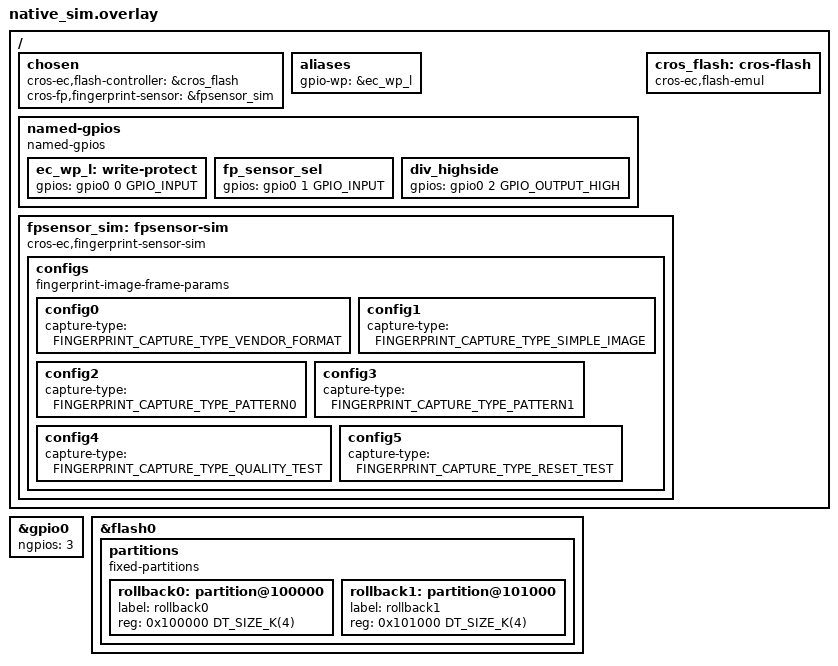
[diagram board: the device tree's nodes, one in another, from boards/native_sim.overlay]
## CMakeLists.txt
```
# Copyright 2024 The ChromiumOS Authors
# Use of this source code is governed by a BSD-style license that can be
# found in the LICENSE file.

cmake_minimum_required(VERSION 3.13.1)
find_package(Zephyr REQUIRED HINTS "${ZEPHYR_BASE}")
project(fpsensor_task_test)

target_sources(app PRIVATE src/mock_fingerprint_algorithm.c)
target_sources_ifdef(CONFIG_LINK_TEST_SUITE_FINGERPRINT_CAPTURE app PRIVATE
	src/fpsensor_capture.cc)
target_sources_ifdef(CONFIG_LINK_TEST_SUITE_FINGERPRINT_ENROLL app PRIVATE
	src/fpsensor_enroll.cc)
target_sources_ifdef(CONFIG_LINK_TEST_SUITE_FINGERPRINT_FINGER_PRESENCE app PRIVATE
	src/fpsensor_finger_presence.cc)
target_sources_ifdef(CONFIG_LINK_TEST_SUITE_FINGERPRINT_INIT app PRIVATE
	src/fpsensor_init.cc)
target_sources_ifdef(CONFIG_LINK_TEST_SUITE_FINGERPRINT_MATCH app PRIVATE
	src/fpsensor_match.cc)
target_sources_ifdef(CONFIG_LINK_TEST_SUITE_FINGERPRINT_SHIM app PRIVATE
	src/fpsensor_shim.cc)
target_sources_ifdef(CONFIG_LINK_TEST_SUITE_FINGERPRINT_TEMPLATE app PRIVATE
	src/fpsensor_template.cc)
target_sources_ifdef(CONFIG_LINK_TEST_SUITE_FINGERPRINT_UTILS app PRIVATE
	src/fpsensor_utils.cc)
target_sources_ifdef(CONFIG_LINK_TEST_SUITE_FINGERPRINT_DEBUG app PRIVATE
	src/fpsensor_debug.cc)
target_sources_ifdef(CONFIG_LINK_TEST_SUITE_FINGERPRINT_COMMANDS app PRIVATE
	src/fpsensor_commands.cc
	src/fpsensor_vendor_command.cc
	src/fpsensor_sdcp_command.cc)
target_sources_ifdef(CONFIG_LINK_TEST_SUITE_FINGERPRINT_FRAME_SIZE app PRIVATE
	src/fpsensor_frame_size.cc)
```

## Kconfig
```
# Copyright 2024 The ChromiumOS Authors
# Use of this source code is governed by a BSD-style license that can be
# found in the LICENSE file.

config LINK_TEST_SUITE_FINGERPRINT_CAPTURE
	bool "Link fingerprint capture tests"
	help
	  Link and execute fingerprint subsystem tests that focus
	  on finger capture.

config LINK_TEST_SUITE_FINGERPRINT_ENROLL
	bool "Link fingerprint enroll tests"
	help
	  Link and execute fingerprint subsystem tests that focus
	  on template enrollment.

config LINK_TEST_SUITE_FINGERPRINT_FINGER_PRESENCE
	bool "Link fingerprint finger presence tests"
	help
	  Link and execute fingerprint subsystem tests that focus
	  on finger presence.

config LINK_TEST_SUITE_FINGERPRINT_INIT
	bool "Link fingerprint init tests"
	help
	  Link and execute fingerprint subsystem tests that focus
	  on initializing TPM seed and context.

config LINK_TEST_SUITE_FINGERPRINT_MATCH
	bool "Link fingerprint match tests"
	help
	  Link and execute fingerprint subsystem tests that focus
	  on finger matching.

config LINK_TEST_SUITE_FINGERPRINT_SHIM
	bool "Link fingerprint shim tests"
	help
	  Link and execute fingerprint subsystem tests that focus
	  on fpsensor shim.

config LINK_TEST_SUITE_FINGERPRINT_TEMPLATE
	bool "Link fingerprint template tests"
	help
	  Link and execute fingerprint subsystem tests that focus
	  on finger templates.

config LINK_TEST_SUITE_FINGERPRINT_UTILS
	bool "Link fingerprint utils tests"
	help
	  Link and execute fingerprint subsystem tests that focus
	  on finger utils.

config LINK_TEST_SUITE_FINGERPRINT_DEBUG
	bool "Link fingerprint debug tests"
	help
	  Link and execute fingerprint subsystem tests that focus
	  on finger debug.

config LINK_TEST_SUITE_FINGERPRINT_COMMANDS
	bool "Link fingerprint commands tests"
	help
	  Link and execute fingerprint subsystem tests that focus
	  on fingerprint host and console commands.

config LINK_TEST_SUITE_FINGERPRINT_FRAME_SIZE
	bool "Link fingerprint frame size tests"
	help
	  Link and execute fingerprint subsystem tests that focus
	  on finger frame size.

config LINK_TEST_SUITE_FINGERPRINT_BTN_IGN
	bool "Link fingerprint btn ign tests"
	help
	  Link and execute fingerprint subsystem tests that focus
	  on btn ign.

source "Kconfig.zephyr"
```

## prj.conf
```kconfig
# Copyright 2024 The ChromiumOS Authors
# Use of this source code is governed by a BSD-style license that can be
# found in the LICENSE file.

CONFIG_TEST=y
CONFIG_ZTEST=y
CONFIG_EMUL=y
CONFIG_FLASH=y
CONFIG_GPIO=y

CONFIG_NATIVE_UART_0_ON_STDINOUT=y

CONFIG_CPP=y
CONFIG_STD_CPP20=y
CONFIG_REQUIRES_FULL_LIBCPP=y

CONFIG_CROS_EC=y
CONFIG_PLATFORM_EC=y
CONFIG_SHIMMED_TASKS=y

CONFIG_COMMON_LIBC_MALLOC=y
CONFIG_COMMON_LIBC_MALLOC_ARENA_SIZE=2048
CONFIG_BORINGSSL_CRYPTO=y

CONFIG_PLATFORM_EC_RANDOM=y
CONFIG_PLATFORM_EC_FINGERPRINT=y
CONFIG_PLATFORM_EC_ROLLBACK=y
CONFIG_PLATFORM_EC_ROLLBACK_SECRET_SIZE=32
CONFIG_PLATFORM_EC_SHA256_SW=y
CONFIG_PLATFORM_EC_SHA256_UNROLLED=y
CONFIG_PLATFORM_EC_BACKLIGHT_LID=n
CONFIG_PLATFORM_EC_CONSOLE_CMD_CHARGEN=n
CONFIG_PLATFORM_EC_SWITCH=n
CONFIG_PLATFORM_EC_FLASH_SIZE_BYTES=0x200000
CONFIG_PLATFORM_EC_HOSTCMD=y

CONFIG_FINGERPRINT_SUBSYSTEM=y
CONFIG_FINGERPRINT_SENSOR=y

CONFIG_FP_ALGORITHM_TEMPLATE_SIZE=32

# Size of the kernel heap memory pool, primarily used by k_malloc()
# and k_free().
CONFIG_HEAP_MEM_POOL_SIZE=1024
```

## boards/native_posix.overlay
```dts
/* Copyright 2023 The ChromiumOS Authors
 * Use of this source code is governed by a BSD-style license that can be
 * found in the LICENSE file.
 */

#include <board-overlays/native_posix.dts>
#include <dt-bindings/gpio_defines.h>
#include <cros/binman.dtsi>

/ {
	chosen {
		cros-ec,flash-controller = &cros_flash;
		cros-fp,fingerprint-sensor = &fpsensor_sim;
	};

	aliases {
		gpio-wp = &ec_wp_l;
	};

	named-gpios {
		compatible = "named-gpios";

		ec_wp_l: write-protect {
			gpios = <&gpio0 0 GPIO_INPUT>;
		};

		fp_sensor_sel: fp_sensor_sel {
			gpios = <&gpio0 1 GPIO_INPUT>;
		};

		div_highside: div_highside {
			gpios = <&gpio0 2 GPIO_OUTPUT_HIGH>;
		};
	};

	cros_flash: cros-flash {
		compatible = "cros-ec,flash-emul";
	};

	fpsensor_sim: fpsensor_sim {
		compatible = "cros-ec,fingerprint-sensor-sim";
		width = <160>;
		height = <160>;
		bits-per-pixel = <8>;
		v4l2-pixel-format = "V4L2_PIX_FMT_GREY";
	};
};

&gpio0 {
	ngpios = <3>;
};

&flash0 {
	partitions {
		compatible = "fixed-partitions";
		#address-cells = <1>;
		#size-cells = <1>;

		/* Rollback region must have erase unit size. */
		rollback0: partition@100000 {
			label = "rollback0";
			reg = <0x100000 DT_SIZE_K(4)>;
		};

		rollback1: partition@101000 {
			label = "rollback1";
			reg = <0x101000 DT_SIZE_K(4)>;
		};
	};
};
```

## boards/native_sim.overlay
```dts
/* Copyright 2023 The ChromiumOS Authors
 * Use of this source code is governed by a BSD-style license that can be
 * found in the LICENSE file.
 */

#include <board-overlays/native_sim.dts>
#include <dt-bindings/gpio_defines.h>
#include <cros/binman.dtsi>

#define FP_SIMULATOR_RAW_IMAGE_PROPS \
	width = <160>; \
	height = <160>; \
	bits-per-pixel = <8>; \
	frame-size = <26260>; \
	v4l2-pixel-format = "V4L2_PIX_FMT_GREY";

#define FP_SIMULATOR_REAL_IMAGE_PROPS \
	width = <160>; \
	height = <160>; \
	bits-per-pixel = <8>; \
	/* Sensor real image size: (160*160) */ \
	frame-size = <25600>; \
	v4l2-pixel-format = "V4L2_PIX_FMT_GREY";

/ {
	chosen {
		cros-ec,flash-controller = &cros_flash;
		cros-fp,fingerprint-sensor = &fpsensor_sim;
	};

	aliases {
		gpio-wp = &ec_wp_l;
	};

	named-gpios {
		compatible = "named-gpios";

		ec_wp_l: write-protect {
			gpios = <&gpio0 0 GPIO_INPUT>;
		};

		fp_sensor_sel: fp_sensor_sel {
			gpios = <&gpio0 1 GPIO_INPUT>;
		};

		div_highside: div_highside {
			gpios = <&gpio0 2 GPIO_OUTPUT_HIGH>;
		};
	};

	cros_flash: cros-flash {
		compatible = "cros-ec,flash-emul";
	};

	fpsensor_sim: fpsensor-sim {
		compatible = "cros-ec,fingerprint-sensor-sim";
		configs {
			compatible = "fingerprint-image-frame-params";
			config0 {
				FP_SIMULATOR_RAW_IMAGE_PROPS
				capture-type = "FINGERPRINT_CAPTURE_TYPE_VENDOR_FORMAT";
			};
			config1 {
				FP_SIMULATOR_REAL_IMAGE_PROPS
				capture-type = "FINGERPRINT_CAPTURE_TYPE_SIMPLE_IMAGE";
			};
			config2 {
				FP_SIMULATOR_REAL_IMAGE_PROPS
				capture-type = "FINGERPRINT_CAPTURE_TYPE_PATTERN0";
			};
			config3 {
				FP_SIMULATOR_REAL_IMAGE_PROPS
				capture-type = "FINGERPRINT_CAPTURE_TYPE_PATTERN1";
			};
			config4 {
				FP_SIMULATOR_RAW_IMAGE_PROPS
				capture-type = "FINGERPRINT_CAPTURE_TYPE_QUALITY_TEST";
			};
			config5 {
				FP_SIMULATOR_REAL_IMAGE_PROPS
				capture-type = "FINGERPRINT_CAPTURE_TYPE_RESET_TEST";
			};
		};
	};
};

&gpio0 {
	ngpios = <3>;
};

&flash0 {
	partitions {
		compatible = "fixed-partitions";
		#address-cells = <1>;
		#size-cells = <1>;

		/* Rollback region must have erase unit size. */
		rollback0: partition@100000 {
			label = "rollback0";
			reg = <0x100000 DT_SIZE_K(4)>;
		};

		rollback1: partition@101000 {
			label = "rollback1";
			reg = <0x101000 DT_SIZE_K(4)>;
		};
	};
};
```

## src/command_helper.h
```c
// Copyright 2025 The ChromiumOS Authors
// Use of this source code is governed by a BSD-style license that can be
// found in the LICENSE file.

#include <drivers/fingerprint.h>
#include <ec_commands.h>
#include <host_command.h>

uint16_t ec_cmd_fp_info_v2(struct ec_response_fp_info_v2 *response)
{
	static const size_t test_info_buffer_size =
		sizeof(struct ec_response_fp_info_v2) +
		sizeof(struct fp_image_frame_params) * NUM_IMAGE_CAPTURE_TYPES;

	struct host_cmd_handler_args args =
		BUILD_HOST_COMMAND_RESPONSE(EC_CMD_FP_INFO, 2, *response);
	args.response_max = test_info_buffer_size;

	return host_command_process(&args);
}
```

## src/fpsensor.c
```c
/* Copyright 2024 The ChromiumOS Authors
 * Use of this source code is governed by a BSD-style license that can be
 * found in the LICENSE file.
 */

#include "mock_fingerprint_algorithm.h"

#include <zephyr/device.h>
#include <zephyr/devicetree.h>
#include <zephyr/drivers/emul.h>
#include <zephyr/drivers/gpio.h>
#include <zephyr/drivers/gpio/gpio_emul.h>
#include <zephyr/fff.h>
#include <zephyr/ztest.h>
#include <zephyr/ztest_assert.h>

#include <drivers/fingerprint.h>
#include <drivers/fingerprint_sim.h>
#include <ec_commands.h>
#include <ec_tasks.h>
#include <fpsensor/fpsensor_state.h>
#include <host_command.h>

DEFINE_FFF_GLOBALS;

FAKE_VALUE_FUNC(int, mkbp_send_event, uint8_t);
FAKE_VALUE_FUNC(int, system_is_locked);

#define fp_sim DEVICE_DT_GET(DT_CHOSEN(cros_fp_fingerprint_sensor))
#define image_size                          \
	FINGERPRINT_SENSOR_REAL_IMAGE_SIZE( \
		DT_CHOSEN(cros_fp_fingerprint_sensor))
uint8_t frame_buffer[image_size];

ZTEST_USER(fpsensor, test_tpm_seed_init)
{
	struct ec_response_fp_encryption_status status;
	struct ec_params_fp_seed params = {
		.struct_version = 4,
		.reserved = 0,
		.seed = "very_secret_32_bytes_of_tpm_seed",
	};

	/* Get FP encryption flags. */
	zassert_ok(ec_cmd_fp_encryption_status(NULL, &status));

	/* Confirm TPM seed is not set */
	zassert_true(status.valid_flags & FP_ENC_STATUS_SEED_SET);
	zassert_false(status.status & FP_ENC_STATUS_SEED_SET);

	/* Set TPM seed. */
	zassert_ok(ec_cmd_fp_seed(NULL, &params));

	/* Get FP encryption flags. */
	zassert_ok(ec_cmd_fp_encryption_status(NULL, &status));

	/* Confirm that FP_ENC_STATUS_SEED_SET is set. */
	zassert_true(status.valid_flags & FP_ENC_STATUS_SEED_SET);
	zassert_true(status.status & FP_ENC_STATUS_SEED_SET);

	/* Try to set TPM seed once again (should fail). */
	zassert_equal(EC_RES_ACCESS_DENIED, ec_cmd_fp_seed(NULL, &params));
}

ZTEST_USER(fpsensor, test_tpm_seed_invalid)
{
	struct ec_params_fp_seed params = {
		/* 0 is not an actual structure version. */
		.struct_version = 0,
		.reserved = 0,
		.seed = "very_secret_32_bytes_of_tpm_seed",
	};

	/* Try to et TPM seed (should fail). */
	zassert_equal(EC_RES_INVALID_PARAM, ec_cmd_fp_seed(NULL, &params));
}

ZTEST_USER(fpsensor, test_set_fp_context)
{
	struct ec_params_fp_context_v1 params = {
		.action = FP_CONTEXT_ASYNC,
		.userid = { 0x1, 0x2, 0x3, 0x4, 0x5, 0x6, 0x7, 0x8 },
	};
	struct ec_response_fp_encryption_status status;

	/* Set context (asynchronously). */
	zassert_ok(ec_cmd_fp_context_v1(NULL, &params));

	/* Now any attempt to set context should return EC_RES_BUSY. */
	zassert_equal(EC_RES_BUSY, ec_cmd_fp_context_v1(NULL, &params));

	/* Now any attempt to get command result should return EC_RES_BUSY. */
	params.action = FP_CONTEXT_GET_RESULT;
	zassert_equal(EC_RES_BUSY, ec_cmd_fp_context_v1(NULL, &params));

	/* Give opportunity for fpsensor task to change mode. */
	k_msleep(1);

	/* Get command result. */
	zassert_ok(ec_cmd_fp_context_v1(NULL, &params));

	/* Get FP encryption flags. */
	zassert_ok(ec_cmd_fp_encryption_status(NULL, &status));

	/* Confirm that FP_CONTEXT_USER_ID_SET is set. */
	zassert_true(status.status & FP_CONTEXT_USER_ID_SET);
}

ZTEST_USER(fpsensor, test_maintenance_mode)
{
	struct ec_params_fp_mode params = {
		.mode = FP_MODE_SENSOR_MAINTENANCE,
	};
	struct ec_response_fp_mode response;
	struct ec_response_fp_info info;
	struct fingerprint_sensor_state state;

	const int dead_pixels = 3;

	/* Confirm that number of dead pixels is unknown. */
	zassert_ok(ec_cmd_fp_info(NULL, &info));
	zassert_equal(FP_ERROR_DEAD_PIXELS(info.errors),
		      FP_ERROR_DEAD_PIXELS_UNKNOWN);

	fingerprint_get_state(fp_sim, &state);
	state.bad_pixels = dead_pixels;
	fingerprint_set_state(fp_sim, &state);

	/* Change fingerprint mode to maintenance. */
	zassert_ok(ec_cmd_fp_mode(NULL, &params, &response));
	zassert_true(response.mode & FP_MODE_SENSOR_MAINTENANCE);

	/* Give opportunity for fpsensor task to change mode. */
	k_msleep(1);

	/* Check that maintenance was ran. */
	fingerprint_get_state(fp_sim, &state);
	zassert_true(state.maintenance_ran);

	/* Confirm that number of dead pixels is correct. */
	zassert_ok(ec_cmd_fp_info(NULL, &info));
	zassert_equal(FP_ERROR_DEAD_PIXELS(info.errors), dead_pixels);

	/*
	 * Confirm that maintenance flag is not set after the maintenance
	 * operation is finished.
	 */
	params.mode = FP_MODE_DONT_CHANGE;
	zassert_ok(ec_cmd_fp_mode(NULL, &params, &response));
	zassert_false(response.mode & FP_MODE_SENSOR_MAINTENANCE);
}

ZTEST_USER(fpsensor, test_fp_frame_raw_image_system_is_locked)
{
	struct ec_params_fp_frame frame_request = {
		.offset = FP_FRAME_INDEX_RAW_IMAGE << FP_FRAME_INDEX_SHIFT,
		.size = image_size,
	};

	/* Lock the system. */
	system_is_locked_fake.return_val = true;

	/*
	 * Confirm that it's not possible to get raw image when system is
	 * locked.
	 */
	zassert_equal(ec_cmd_fp_frame(NULL, &frame_request, frame_buffer),
		      EC_RES_ACCESS_DENIED);
}

ZTEST_USER(fpsensor, test_fp_frame_raw_image_size_too_big)
{
	struct ec_params_fp_frame frame_request = {
		.offset = FP_FRAME_INDEX_RAW_IMAGE << FP_FRAME_INDEX_SHIFT,
		.size = image_size + 1,
	};

	/*
	 * Confirm that FP_FRAME host command will return an error when
	 * requested more than fingerprint frame size.
	 */
	zassert_equal(ec_cmd_fp_frame(NULL, &frame_request, frame_buffer), EC_RES_INVALID_PARAM);
}

ZTEST_USER(fpsensor, test_fp_frame_raw_image_bad_offset)
{
	struct ec_params_fp_frame frame_request = {
		.offset = ((FP_FRAME_INDEX_RAW_IMAGE << FP_FRAME_INDEX_SHIFT) | (image_size + 1)),
		.size = 1,
	};

	/*
	 * Confirm that FP_FRAME host command will return an error when
	 * trying to read from bad offset.
	 */
	zassert_equal(ec_cmd_fp_frame(NULL, &frame_request, frame_buffer), EC_RES_INVALID_PARAM);
}

ZTEST_USER(fpsensor, test_finger_match_no_templates_mkbp_event)
{
	struct ec_params_fp_mode params = {
		.mode = FP_MODE_MATCH,
	};
	struct ec_response_fp_mode response;
	struct fingerprint_sensor_state state;
	uint32_t fp_events;

	/* Switch mode to match. */
	zassert_ok(ec_cmd_fp_mode(NULL, &params, &response));
	zassert_true(response.mode & FP_MODE_MATCH);

	/* Give opportunity for fpsensor task to change mode. */
	k_msleep(1);

	/* Put finger on the sensor. */
	fingerprint_get_state(fp_sim, &state);
	state.finger_state = FINGERPRINT_FINGER_STATE_PRESENT;
	fingerprint_set_state(fp_sim, &state);

	/* Ping fpsensor task. */
	fingerprint_run_callback(fp_sim);

	/* Give opportunity for fpsensor task to process event. */
	k_msleep(1);

	/* Confirm MKBP event was sent. */
	zassert_equal(mkbp_send_event_fake.call_count, 1);
	zassert_equal(mkbp_send_event_fake.arg0_val, EC_MKBP_EVENT_FINGERPRINT);

	/*
	 * Confirm that:
	 * - MKBP event is FP_MATCH
	 * - Match failed with NO_TEMPLATES
	 * - Finger ID is FP_NO_SUCH_TEMPLATE
	 */
	fp_get_next_event((uint8_t *)&fp_events);
	zassert_true(fp_events & EC_MKBP_FP_MATCH);
	zassert_equal(EC_MKBP_FP_ERRCODE(fp_events), EC_MKBP_FP_ERR_MATCH_NO_TEMPLATES);
	zassert_equal(EC_MKBP_FP_MATCH_IDX(fp_events), FP_NO_SUCH_TEMPLATE & 0xF);
}

ZTEST_USER(fpsensor, test_finger_match_no_templates_mode_cleared)
{
	struct ec_params_fp_mode params = {
		.mode = FP_MODE_MATCH,
	};
	struct ec_response_fp_mode response;
	struct fingerprint_sensor_state state;

	/* Switch mode to match. */
	zassert_ok(ec_cmd_fp_mode(NULL, &params, &response));
	zassert_true(response.mode & FP_MODE_MATCH);

	/* Give opportunity for fpsensor task to change mode. */
	k_msleep(1);

	/* Put finger on the sensor. */
	fingerprint_get_state(fp_sim, &state);
	state.finger_state = FINGERPRINT_FINGER_STATE_PRESENT;
	fingerprint_set_state(fp_sim, &state);

	/* Ping fpsensor task. */
	fingerprint_run_callback(fp_sim);

	/* Give opportunity for fpsensor task to process event. */
	k_msleep(1);

	/* Confirm that capture mode is not enabled. */
	params.mode = FP_MODE_DONT_CHANGE;
	zassert_ok(ec_cmd_fp_mode(NULL, &params, &response));
	zassert_false(response.mode & FP_MODE_MATCH);
}

static void *fpsensor_setup(void)
{
	/* Start shimmed tasks. */
	start_ec_tasks();
	k_msleep(100);

	return NULL;
}

static void fpsensor_before(void *f)
{
	struct fingerprint_sensor_state state = {
		.bad_pixels = 0,
		.maintenance_ran = false,
		.detect_mode = false,
		.low_power_mode = false,
		.finger_state = FINGERPRINT_FINGER_STATE_NONE,
		.acquire_image_result = FINGERPRINT_SENSOR_SCAN_GOOD,
		.last_acquire_image_mode = -1,
	};

	fingerprint_set_state(fp_sim, &state);
	RESET_FAKE(mkbp_send_event);
	RESET_FAKE(system_is_locked);
}

ZTEST_SUITE(fpsensor, NULL, fpsensor_setup, fpsensor_before, NULL, NULL);
```

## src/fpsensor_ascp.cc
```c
/* Copyright 2026 The ChromiumOS Authors
 * Use of this source code is governed by a BSD-style license that can be
 * found in the LICENSE file.
 */

#include "common.h"
#include "console.h"
#include "fpsensor/fpsensor_auth_crypto.h"
#include "fpsensor/fpsensor_auth_secrets.h"
#include "openssl/mem.h"
#include "system.h"

#include <zephyr/drivers/emul.h>
#include <zephyr/fff.h>
#include <zephyr/ztest.h>

#include <algorithm>
#include <ascp/ascp.h>
#include <ec_commands.h>
#include <fpsensor/fpsensor.h>
#include <fpsensor/fpsensor_state_driver.h>
#include <fpsensor/fpsensor_utils.h>
#include <fpsensor_driver.h>
#include <host_command.h>
#include <mkbp_event.h>
#include <ranges>

DEFINE_FFF_GLOBALS;

FAKE_VALUE_FUNC(int, mkbp_send_event, uint8_t);

static constexpr std::array<uint8_t, 32> sk_f = {
	0x64, 0xfb, 0xd5, 0x8f, 0x6b, 0x57, 0x2a, 0x41, 0xef, 0x00, 0x0e,
	0x18, 0x92, 0xf8, 0xb5, 0x52, 0xc7, 0x41, 0x34, 0x35, 0xb1, 0xce,
	0x7c, 0x11, 0xfc, 0xf5, 0xa5, 0x94, 0x97, 0xaa, 0xc4, 0x91
};

static constexpr std::array<uint8_t, 65> pk_f = {
	0x04, 0x48, 0x04, 0x5c, 0x21, 0x5b, 0x8d, 0x9b, 0x23, 0x31, 0x95,
	0x0e, 0x2a, 0x8d, 0x8f, 0x26, 0x22, 0x66, 0xe9, 0x59, 0xc2, 0x37,
	0xc9, 0x4f, 0x94, 0x73, 0x27, 0xc2, 0xb1, 0x11, 0xa0, 0x01, 0x78,
	0x13, 0x2f, 0x08, 0x9e, 0x94, 0xe7, 0x6d, 0x58, 0x76, 0xa1, 0x1a,
	0x20, 0xda, 0x0c, 0xc1, 0xef, 0x91, 0xaf, 0xb1, 0x5d, 0x48, 0x81,
	0x1b, 0x6b, 0xe1, 0x6e, 0xc0, 0xd5, 0xfb, 0x9d, 0x69, 0x82
};

static constexpr std::array<uint8_t, 32> sk_g = {
	0x2e, 0xdd, 0x7a, 0x67, 0x2f, 0x22, 0x21, 0x5c, 0x23, 0x80, 0xf0,
	0x80, 0x29, 0x5c, 0x6d, 0x95, 0xe9, 0x0b, 0x31, 0x9c, 0x17, 0xc1,
	0xc6, 0xcc, 0xe3, 0xbe, 0x9b, 0x7c, 0xd7, 0x2a, 0x18, 0x3f
};

static constexpr std::array<uint8_t, 65> pk_g = {
	0x04, 0x65, 0xf5, 0xd4, 0x79, 0x82, 0x7e, 0xc1, 0xaf, 0x28, 0x2e,
	0x4b, 0xd0, 0xa6, 0xcb, 0xf4, 0xf4, 0xf5, 0x16, 0x63, 0xa6, 0x85,
	0x40, 0xdc, 0xa4, 0x26, 0xe8, 0x63, 0xc3, 0xa8, 0x52, 0xd3, 0x25,
	0x42, 0x8d, 0xd4, 0x7d, 0x85, 0x30, 0x6c, 0x16, 0x6e, 0x99, 0x24,
	0x65, 0x5c, 0x6d, 0x9b, 0x04, 0xfe, 0xfb, 0x83, 0x49, 0x9d, 0xa9,
	0x2a, 0xae, 0x75, 0x3e, 0x79, 0xdc, 0xa1, 0x80, 0x6e, 0x6e
};

static std::array<uint8_t, 32> get_ascp_sk_f_custom_sk_f;
static int get_ascp_sk_f_custom_ret;

const uint8_t *get_ascp_sk_f()
{
	if (get_ascp_sk_f_custom_ret != 0)
		return nullptr;
	return get_ascp_sk_f_custom_sk_f.data();
}

struct ascp_api ascp_api_instance = {
	.get_sk_f = get_ascp_sk_f,
};

ZTEST(hc_fp_ascp, test_fp_ascp_establish_ok)
{
	int ret;
	ec_params_fp_ascp_establish params;
	std::ranges::copy(pk_g, std::begin(params.pk_g));

	ret = ec_cmd_fp_ascp_establish(nullptr, &params);
	zassert_equal(EC_RES_SUCCESS, ret);

	bssl::UniquePtr<EC_KEY> public_key = create_ec_key_from_pubkey(
		*reinterpret_cast<const fp_elliptic_curve_public_key *>(
			&pk_f[1]));
	bssl::UniquePtr<EC_KEY> private_key =
		create_ec_key_from_privkey(sk_g.data(), sk_g.size());
	zassert_not_equal(public_key, nullptr);
	zassert_not_equal(private_key, nullptr);

	std::array<uint8_t, FP_PAIRING_KEY_LEN> host_pairing_key;
	ret = generate_ecdh_shared_secret_without_kdf(*private_key, *public_key,
						      host_pairing_key);
	zassert_equal(EC_SUCCESS, ret);

	zassert_true(std::ranges::equal(host_pairing_key, pairing_key));
}

ZTEST(hc_fp_ascp, test_fp_ascp_establish_pk_g_first_not_ok)
{
	int ret;
	ec_params_fp_ascp_establish params;
	std::ranges::copy(pk_g, std::begin(params.pk_g));

	params.pk_g[0] = 0x05;

	ret = ec_cmd_fp_ascp_establish(nullptr, &params);
	zassert_equal(EC_RES_INVALID_PARAM, ret);
}

ZTEST(hc_fp_ascp, test_fp_ascp_establish_pk_g_later_not_ok)
{
	int ret;
	ec_params_fp_ascp_establish params;
	std::ranges::copy(pk_g, std::begin(params.pk_g));

	params.pk_g[1] = 0x00;

	ret = ec_cmd_fp_ascp_establish(nullptr, &params);
	zassert_equal(EC_RES_INVALID_PARAM, ret);
}

ZTEST(hc_fp_ascp, test_fp_ascp_establish_get_ascp_sk_f_not_ok)
{
	int ret;
	ec_params_fp_ascp_establish params;
	std::ranges::copy(pk_g, std::begin(params.pk_g));

	get_ascp_sk_f_custom_ret = -1;

	ret = ec_cmd_fp_ascp_establish(nullptr, &params);
	zassert_equal(EC_RES_ERROR, ret);
}

ZTEST(hc_fp_ascp, test_fp_ascp_establish_sk_f_not_ok)
{
	int ret;
	ec_params_fp_ascp_establish params;
	std::ranges::copy(pk_g, std::begin(params.pk_g));

	std::ranges::fill(get_ascp_sk_f_custom_sk_f, 0);

	ret = ec_cmd_fp_ascp_establish(nullptr, &params);
	zassert_equal(EC_RES_ERROR, ret);
}

static void reset(void *data)
{
	ARG_UNUSED(data);

	get_ascp_sk_f_custom_ret = 0;
	std::ranges::copy(sk_f, std::begin(get_ascp_sk_f_custom_sk_f));
}

ZTEST_SUITE(hc_fp_ascp, nullptr, nullptr, reset, reset, nullptr);
```

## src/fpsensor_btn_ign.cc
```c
/* Copyright 2026 The ChromiumOS Authors
 * Use of this source code is governed by a BSD-style license that can be
 * found in the LICENSE file.
 */

#include "compile_time_macros.h"
#include "fpsensor/fpsensor_btn_ign.h"

#include <zephyr/fff.h>
#include <zephyr/ztest.h>

#include <cstdint>
#include <mkbp_event.h>

DEFINE_FFF_GLOBALS;

FAKE_VALUE_FUNC(int, mkbp_send_event, uint8_t);

/* Define mocks for the functions declared in drivers/btn_ign.h */
FAKE_VOID_FUNC(btn_ign_activate);
FAKE_VOID_FUNC(btn_ign_deactivate);

static void fpsensor_btn_ign_before(void *data)
{
	RESET_FAKE(btn_ign_activate);
	RESET_FAKE(btn_ign_deactivate);
}

ZTEST_SUITE(fpsensor_btn_ign, NULL, NULL, fpsensor_btn_ign_before, NULL, NULL);

ZTEST(fpsensor_btn_ign, test_update_btn_ign_enroll)
{
	update_btn_ign(FP_MODE_ENROLL_SESSION);

	zassert_equal(btn_ign_activate_fake.call_count, 1,
		      "btn_ign_activate should be called");
	zassert_equal(btn_ign_deactivate_fake.call_count, 0,
		      "btn_ign_deactivate should not be called");
}

ZTEST(fpsensor_btn_ign, test_update_btn_ign_match)
{
	update_btn_ign(FP_MODE_MATCH);

	zassert_equal(btn_ign_activate_fake.call_count, 1,
		      "btn_ign_activate should be called");
	zassert_equal(btn_ign_deactivate_fake.call_count, 0,
		      "btn_ign_deactivate should not be called");
}

ZTEST(fpsensor_btn_ign, test_update_btn_ign_combined)
{
	update_btn_ign(FP_MODE_ENROLL_SESSION | FP_MODE_MATCH);

	zassert_equal(btn_ign_activate_fake.call_count, 1,
		      "btn_ign_activate should be called");
	zassert_equal(btn_ign_deactivate_fake.call_count, 0,
		      "btn_ign_deactivate should not be called");
}

ZTEST(fpsensor_btn_ign, test_update_btn_ign_other)
{
	update_btn_ign(0);

	zassert_equal(btn_ign_activate_fake.call_count, 0,
		      "btn_ign_activate should not be called");
	zassert_equal(btn_ign_deactivate_fake.call_count, 1,
		      "btn_ign_deactivate should be called");

	update_btn_ign(FP_MODE_RESET_SENSOR);

	zassert_equal(btn_ign_activate_fake.call_count, 0,
		      "btn_ign_activate should not be called");
	zassert_equal(btn_ign_deactivate_fake.call_count, 2,
		      "btn_ign_deactivate should be called");
}
```

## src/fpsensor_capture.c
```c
/* Copyright 2024 The ChromiumOS Authors
 * Use of this source code is governed by a BSD-style license that can be
 * found in the LICENSE file.
 */

#include <zephyr/device.h>
#include <zephyr/devicetree.h>
#include <zephyr/drivers/emul.h>
#include <zephyr/drivers/gpio.h>
#include <zephyr/drivers/gpio/gpio_emul.h>
#include <zephyr/fff.h>
#include <zephyr/ztest.h>
#include <zephyr/ztest_assert.h>

#include <drivers/fingerprint.h>
#include <drivers/fingerprint_sim.h>
#include <ec_commands.h>
#include <ec_tasks.h>
#include <fpsensor/fpsensor_state.h>
#include <host_command.h>

DEFINE_FFF_GLOBALS;

FAKE_VALUE_FUNC(int, mkbp_send_event, uint8_t);

#define fp_sim DEVICE_DT_GET(DT_CHOSEN(cros_fp_fingerprint_sensor))
#define IMAGE_SIZE                          \
	FINGERPRINT_SENSOR_REAL_IMAGE_SIZE( \
		DT_CHOSEN(cros_fp_fingerprint_sensor))
static uint8_t image_buffer[IMAGE_SIZE];
static uint8_t frame_buffer[IMAGE_SIZE];

ZTEST_USER(fpsensor_capture, test_finger_capture_simple_image_detection_enabled)
{
	struct ec_params_fp_mode params = {
		.mode = FP_MODE_CAPTURE |
			(FP_CAPTURE_SIMPLE_IMAGE << FP_MODE_CAPTURE_TYPE_SHIFT),
	};
	struct ec_response_fp_mode response;
	struct fingerprint_sensor_state state;

	/* Switch mode to capture. */
	zassert_ok(ec_cmd_fp_mode(NULL, &params, &response));
	zassert_true(response.mode & FP_MODE_CAPTURE);
	zassert_equal(FP_CAPTURE_TYPE(response.mode), FP_CAPTURE_SIMPLE_IMAGE);

	/* Give opportunity for fpsensor task to change mode. */
	k_msleep(1);

	/* Confirm that detect mode was enabled. */
	fingerprint_get_state(fp_sim, &state);
	zassert_true(state.detect_mode);

	/* Disable finger capture. */
	params.mode = 0;
	zassert_ok(ec_cmd_fp_mode(NULL, &params, &response));
	zassert_false(response.mode & FP_MODE_CAPTURE);

	/* Give opportunity for fpsensor task to change mode. */
	k_msleep(1);

	/* Confirm that detect mode was disabled. */
	fingerprint_get_state(fp_sim, &state);
	zassert_false(state.detect_mode);
}

ZTEST_USER(fpsensor_capture, test_finger_capture_simple_image_mode_is_correct)
{
	struct ec_params_fp_mode params = {
		.mode = FP_MODE_CAPTURE |
			(FP_CAPTURE_SIMPLE_IMAGE << FP_MODE_CAPTURE_TYPE_SHIFT),
	};
	struct ec_response_fp_mode response;
	struct fingerprint_sensor_state state;

	/* Switch mode to capture. */
	zassert_ok(ec_cmd_fp_mode(NULL, &params, &response));
	zassert_true(response.mode & FP_MODE_CAPTURE);
	zassert_equal(FP_CAPTURE_TYPE(response.mode), FP_CAPTURE_SIMPLE_IMAGE);

	/* Give opportunity for fpsensor task to change mode. */
	k_msleep(1);

	/* Put finger on the sensor. */
	fingerprint_get_state(fp_sim, &state);
	state.finger_state = FINGERPRINT_FINGER_STATE_PRESENT;
	fingerprint_set_state(fp_sim, &state);

	/* Ping fpsensor task. */
	fingerprint_run_callback(fp_sim);

	/* Give opportunity for fpsensor task process event. */
	k_msleep(1);

	/* Confirm that correct mode was passed to driver. */
	fingerprint_get_state(fp_sim, &state);
	zassert_equal(state.last_acquire_image_mode,
		      FINGERPRINT_CAPTURE_TYPE_SIMPLE_IMAGE);
}

ZTEST_USER(fpsensor_capture, test_finger_capture_finger_state_partial)
{
	struct ec_params_fp_mode params = {
		.mode = FP_MODE_CAPTURE |
			(FP_CAPTURE_SIMPLE_IMAGE << FP_MODE_CAPTURE_TYPE_SHIFT),
	};
	struct ec_response_fp_mode response;
	struct fingerprint_sensor_state state;

	/* Switch mode to capture. */
	zassert_ok(ec_cmd_fp_mode(NULL, &params, &response));
	zassert_true(response.mode & FP_MODE_CAPTURE);
	zassert_equal(FP_CAPTURE_TYPE(response.mode), FP_CAPTURE_SIMPLE_IMAGE);

	/* Give opportunity for fpsensor task to change mode. */
	k_msleep(1);

	/* Put finger on the sensor (partially). */
	fingerprint_get_state(fp_sim, &state);
	state.finger_state = FINGERPRINT_FINGER_STATE_PARTIAL;
	fingerprint_set_state(fp_sim, &state);

	/* Ping fpsensor task. */
	fingerprint_run_callback(fp_sim);

	/* Give opportunity for fpsensor task process event. */
	k_msleep(1);

	/* Confirm that no scan was performed. */
	fingerprint_get_state(fp_sim, &state);
	zassert_equal(state.last_acquire_image_mode, -1);

	/* Confirm that capture mode is still enabled. */
	params.mode = FP_MODE_DONT_CHANGE;
	zassert_ok(ec_cmd_fp_mode(NULL, &params, &response));
	zassert_true(response.mode & FP_MODE_CAPTURE);
}

ZTEST_USER(fpsensor_capture, test_finger_capture_finger_state_none)
{
	struct ec_params_fp_mode params = {
		.mode = FP_MODE_CAPTURE |
			(FP_CAPTURE_SIMPLE_IMAGE << FP_MODE_CAPTURE_TYPE_SHIFT),
	};
	struct ec_response_fp_mode response;
	struct fingerprint_sensor_state state;

	/* Switch mode to capture. */
	zassert_ok(ec_cmd_fp_mode(NULL, &params, &response));
	zassert_true(response.mode & FP_MODE_CAPTURE);
	zassert_equal(FP_CAPTURE_TYPE(response.mode), FP_CAPTURE_SIMPLE_IMAGE);

	/* Give opportunity for fpsensor task to change mode. */
	k_msleep(1);

	/* Ping fpsensor task. */
	fingerprint_run_callback(fp_sim);

	/* Give opportunity for fpsensor task process event. */
	k_msleep(1);

	/* Confirm that no scan was performed. */
	fingerprint_get_state(fp_sim, &state);
	zassert_equal(state.last_acquire_image_mode, -1);

	/* Confirm that capture mode is still enabled. */
	params.mode = FP_MODE_DONT_CHANGE;
	zassert_ok(ec_cmd_fp_mode(NULL, &params, &response));
	zassert_true(response.mode & FP_MODE_CAPTURE);
}

ZTEST_USER(fpsensor_capture, test_finger_capture_simple_image_scan_too_fast)
{
	struct ec_params_fp_mode params = {
		.mode = FP_MODE_CAPTURE |
			(FP_CAPTURE_SIMPLE_IMAGE << FP_MODE_CAPTURE_TYPE_SHIFT),
	};
	struct ec_response_fp_mode response;
	struct fingerprint_sensor_state state;

	/* Switch mode to capture. */
	zassert_ok(ec_cmd_fp_mode(NULL, &params, &response));
	zassert_true(response.mode & FP_MODE_CAPTURE);
	zassert_equal(FP_CAPTURE_TYPE(response.mode), FP_CAPTURE_SIMPLE_IMAGE);

	/* Give opportunity for fpsensor task to change mode. */
	k_msleep(1);

	/* Put finger on the sensor. */
	fingerprint_get_state(fp_sim, &state);
	state.finger_state = FINGERPRINT_FINGER_STATE_PRESENT;
	state.acquire_image_result = FINGERPRINT_SENSOR_SCAN_TOO_FAST;
	fingerprint_set_state(fp_sim, &state);

	/* Ping fpsensor task. */
	fingerprint_run_callback(fp_sim);

	/* Give opportunity for fpsensor task process event. */
	k_msleep(1);

	/* Confirm that capture mode is still enabled. */
	params.mode = FP_MODE_DONT_CHANGE;
	zassert_ok(ec_cmd_fp_mode(NULL, &params, &response));
	zassert_true(response.mode & FP_MODE_CAPTURE);
}

ZTEST_USER(fpsensor_capture,
	   test_finger_capture_simple_image_scan_success_mode_cleared)
{
	struct ec_params_fp_mode params = {
		.mode = FP_MODE_CAPTURE |
			(FP_CAPTURE_SIMPLE_IMAGE << FP_MODE_CAPTURE_TYPE_SHIFT),
	};
	struct ec_response_fp_mode response;
	struct fingerprint_sensor_state state;

	/* Switch mode to capture. */
	zassert_ok(ec_cmd_fp_mode(NULL, &params, &response));
	zassert_true(response.mode & FP_MODE_CAPTURE);
	zassert_equal(FP_CAPTURE_TYPE(response.mode), FP_CAPTURE_SIMPLE_IMAGE);

	/* Give opportunity for fpsensor task to change mode. */
	k_msleep(1);

	/* Put finger on the sensor. */
	fingerprint_get_state(fp_sim, &state);
	state.finger_state = FINGERPRINT_FINGER_STATE_PRESENT;
	fingerprint_set_state(fp_sim, &state);

	/* Ping fpsensor task. */
	fingerprint_run_callback(fp_sim);

	/* Give opportunity for fpsensor task process event. */
	k_msleep(1);

	/* Confirm that capture mode is not enabled. */
	params.mode = FP_MODE_DONT_CHANGE;
	zassert_ok(ec_cmd_fp_mode(NULL, &params, &response));
	zassert_false(response.mode & FP_MODE_CAPTURE);
}

ZTEST_USER(fpsensor_capture,
	   test_finger_capture_simple_image_scan_success_mkbp_event)
{
	struct ec_params_fp_mode params = {
		.mode = FP_MODE_CAPTURE |
			(FP_CAPTURE_SIMPLE_IMAGE << FP_MODE_CAPTURE_TYPE_SHIFT),
	};
	struct ec_response_fp_mode response;
	struct fingerprint_sensor_state state;
	uint32_t fp_events;

	/* Switch mode to capture. */
	zassert_ok(ec_cmd_fp_mode(NULL, &params, &response));
	zassert_true(response.mode & FP_MODE_CAPTURE);
	zassert_equal(FP_CAPTURE_TYPE(response.mode), FP_CAPTURE_SIMPLE_IMAGE);

	/* Give opportunity for fpsensor task to change mode. */
	k_msleep(1);

	/* Put finger on the sensor. */
	fingerprint_get_state(fp_sim, &state);
	state.finger_state = FINGERPRINT_FINGER_STATE_PRESENT;
	fingerprint_set_state(fp_sim, &state);

	/* Ping fpsensor task. */
	fingerprint_run_callback(fp_sim);

	/* Give opportunity for fpsensor task to process event. */
	k_msleep(1);

	/* Confirm MKBP event was sent. */
	zassert_equal(mkbp_send_event_fake.call_count, 1);
	zassert_equal(mkbp_send_event_fake.arg0_val, EC_MKBP_EVENT_FINGERPRINT);

	/* Confirm that FP_IMAGE_READY MKBP event is sent. */
	fp_get_next_event((uint8_t *)&fp_events);
	zassert_true(fp_events & EC_MKBP_FP_IMAGE_READY);
}

ZTEST_USER(fpsensor_capture,
	   test_finger_capture_simple_image_scan_success_get_frame)
{
	struct ec_params_fp_mode params = {
		.mode = FP_MODE_CAPTURE |
			(FP_CAPTURE_SIMPLE_IMAGE << FP_MODE_CAPTURE_TYPE_SHIFT),
	};
	struct ec_response_fp_mode response;
	struct fingerprint_sensor_state state;
	struct ec_params_fp_frame frame_request = {
		.offset = FP_FRAME_INDEX_RAW_IMAGE << FP_FRAME_INDEX_SHIFT,
		.size = IMAGE_SIZE,
	};

	/* Switch mode to capture. */
	zassert_ok(ec_cmd_fp_mode(NULL, &params, &response));
	zassert_true(response.mode & FP_MODE_CAPTURE);
	zassert_equal(FP_CAPTURE_TYPE(response.mode), FP_CAPTURE_SIMPLE_IMAGE);

	/* Give opportunity for fpsensor task to change mode. */
	k_msleep(1);

	/* Put finger on the sensor. */
	fingerprint_get_state(fp_sim, &state);
	state.finger_state = FINGERPRINT_FINGER_STATE_PRESENT;
	fingerprint_set_state(fp_sim, &state);

	/* Prepare image. */
	memset(image_buffer, 1, IMAGE_SIZE);

	/* Load image to simulator. */
	fingerprint_load_image(fp_sim, image_buffer, IMAGE_SIZE);

	/* Ping fpsensor task. */
	fingerprint_run_callback(fp_sim);

	/* Give opportunity for fpsensor task process event. */
	k_msleep(1);

	/* Get fingerprint raw image and compare buffers. */
	zassert_ok(ec_cmd_fp_frame(NULL, &frame_request, frame_buffer));
	zassert_mem_equal(frame_buffer, image_buffer, IMAGE_SIZE);
}

static void *fpsensor_setup(void)
{
	/* Start shimmed tasks. */
	start_ec_tasks();
	k_msleep(100);

	return NULL;
}

static void fpsensor_before(void *f)
{
	struct fingerprint_sensor_state state = {
		.bad_pixels = 0,
		.maintenance_ran = false,
		.detect_mode = false,
		.low_power_mode = false,
		.finger_state = FINGERPRINT_FINGER_STATE_NONE,
		.init_result = 0,
		.deinit_result = 0,
		.config_result = 0,
		.get_info_result = 0,
		.acquire_image_result = FINGERPRINT_SENSOR_SCAN_GOOD,
		.last_acquire_image_mode = -1,
	};

	fingerprint_set_state(fp_sim, &state);
	RESET_FAKE(mkbp_send_event);
}

ZTEST_SUITE(fpsensor_capture, NULL, fpsensor_setup, fpsensor_before, NULL,
	    NULL);
```

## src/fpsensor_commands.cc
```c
/* Copyright 2026 The ChromiumOS Authors
 * Use of this source code is governed by a BSD-style license that can be
 * found in the LICENSE file.
 */

#include <zephyr/fff.h>

#include <mkbp_event.h>

DEFINE_FFF_GLOBALS;

FAKE_VALUE_FUNC(int, mkbp_send_event, uint8_t);
```

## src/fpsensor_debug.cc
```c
/* Copyright 2024 The ChromiumOS Authors
 * Use of this source code is governed by a BSD-style license that can be
 * found in the LICENSE file.
 */
#include "common.h"
#include "console.h"
#include "system.h"

#include <stdio.h>

#include <zephyr/fff.h>
#include <zephyr/sys/util.h>
#include <zephyr/ztest.h>

#include <algorithm>
#include <array>
#include <ec_commands.h>
#include <fingerprint/v4l2_types.h>
#include <fpsensor/fpsensor_state_driver.h>
#include <fpsensor/fpsensor_utils.h>
#include <fpsensor_driver.h>
#include <mkbp_event.h>
#include <rollback.h>

#define fp_sensor_dev DEVICE_DT_GET(DT_CHOSEN(cros_fp_fingerprint_sensor))

static_assert(sizeof(struct fp_image_frame_params) ==
		      sizeof(struct fingerprint_image_frame_params),
	      "Frame param structures must be the same size");

int get_image_frame_params(struct fp_image_frame_params &image_frame_params,
			   enum fp_capture_type capture_type);

static int is_locked;

int system_is_locked(void)
{
	return is_locked;
}

DEFINE_FFF_GLOBALS;

FAKE_VALUE_FUNC(int, mkbp_send_event, uint8_t);

ZTEST_SUITE(fpsensor_debug, NULL, NULL, NULL, NULL, NULL);

ZTEST(fpsensor_debug, test_console_fpinfo)
{
	/* System is unlocked. */
	is_locked = 0;

	char console_input[] = "fpinfo";
	int rv = shell_execute_cmd(get_ec_shell(), console_input);
	zassert_equal(rv, EC_SUCCESS);
}

/* TODO(b/371647536): Add other tests of commands in fpsensor_debug to verify
 * entire handlers.
 */
ZTEST(fpsensor_debug, test_command_fpupload_success)
{
	/* System is unlocked. */
	is_locked = 0;

	char console_input[] = "fpupload 52 image";
	int rv = shell_execute_cmd(get_ec_shell(), console_input);
	zassert_equal(rv, EC_SUCCESS);
}

ZTEST(fpsensor_debug, test_command_fpupload_system_is_locked)
{
	/* System is locked. */
	is_locked = 1;

	/* Test for the case when access is denied. */
	char console_input[] = "fpupload 52 image";
	int rv = shell_execute_cmd(get_ec_shell(), console_input);
	zassert_equal(rv, EC_ERROR_ACCESS_DENIED);
}

ZTEST(fpsensor_debug, test_command_fpupload_one_argument)
{
	/* System is unlocked. */
	is_locked = 0;

	char console_input[] = "fpupload 52";
	int rv = shell_execute_cmd(get_ec_shell(), console_input);
	zassert_equal(rv, EC_ERROR_PARAM_COUNT);
}

ZTEST(fpsensor_debug, test_command_fpupload_three_arguments)
{
	/* System is unlocked. */
	is_locked = 0;

	char console_input[] = "fpupload 52 image 78";
	int rv = shell_execute_cmd(get_ec_shell(), console_input);
	zassert_equal(rv, EC_ERROR_PARAM_COUNT);
}

ZTEST(fpsensor_debug, test_command_fpupload_negative_offset)
{
	/* System is unlocked. */
	is_locked = 0;

	char console_input[] = "fpupload -1 image";
	int rv = shell_execute_cmd(get_ec_shell(), console_input);
	zassert_equal(rv, EC_ERROR_PARAM1);
}

ZTEST(fpsensor_debug,
      test_command_fpupload_offset_equal_image_size_minus_image_offset)

{
	/* System is unlocked. */
	is_locked = 0;

	char console_input[] = "fpupload " STRINGIFY(UINT32_MAX) " image";
	snprintf(console_input, sizeof(console_input),
		 "fpupload %" PRIu32 " image",
		 FP_SENSOR_IMAGE_SIZE - FP_SENSOR_IMAGE_OFFSET);
	int rv = shell_execute_cmd(get_ec_shell(), console_input);
	zassert_equal(rv, EC_ERROR_PARAM1);
}

ZTEST(fpsensor_debug, test_command_fpupload_correct_uploaded_values)
{
	/* System is unlocked. */
	is_locked = 0;

	std::ranges::fill(fp_buffer, fp_buffer + FP_SENSOR_IMAGE_SIZE, 0);
	char console_input[] = "fpupload 0 f16e38";
	int rv = shell_execute_cmd(get_ec_shell(), console_input);
	zassert_equal(rv, EC_SUCCESS);
	zassert_equal(fp_buffer[FP_SENSOR_IMAGE_OFFSET], 241);
	zassert_equal(fp_buffer[FP_SENSOR_IMAGE_OFFSET + 1], 110);
	zassert_equal(fp_buffer[FP_SENSOR_IMAGE_OFFSET + 2], 56);
}

/* TODO(b/371647536): Add other tests of commands in fpsensor_debug to verify
 * entire handlers.
 */
ZTEST(fpsensor_debug, test_command_fpcapture_system_is_locked)
{
	/* System is locked. */
	is_locked = 1;

	char console_input[] = "fpcapture";
	int rv = shell_execute_cmd(get_ec_shell(), console_input);
	zassert_equal(rv, EC_ERROR_ACCESS_DENIED);
}

ZTEST(fpsensor_debug, test_command_fpcapture_mode_is_negative)
{
	/* System is unlocked. */
	is_locked = 0;

	char console_input[] = "fpcapture -1";
	int rv = shell_execute_cmd(get_ec_shell(), console_input);
	zassert_equal(rv, EC_ERROR_PARAM1);
}

ZTEST(fpsensor_debug, test_command_fpcapture_mode_is_too_large)
{
	/* System is unlocked. */
	is_locked = 0;

	char console_input[] = "fpcapture 56";
	snprintf(console_input, sizeof(console_input), "fpcapture %d",
		 FP_CAPTURE_TYPE_MAX);
	int rv = shell_execute_cmd(get_ec_shell(), console_input);
	zassert_equal(rv, EC_ERROR_PARAM1);
}

/* TODO(b/371647536): Add other tests of commands in fpsensor_debug to verify
 * entire handlers.
 */
ZTEST(fpsensor_debug, test_command_fpenroll)
{
	/* System is locked. */
	is_locked = 1;

	char console_input[] = "fpenroll";
	int rv = shell_execute_cmd(get_ec_shell(), console_input);
	zassert_equal(rv, EC_ERROR_ACCESS_DENIED);
}

enum ec_error_list
upload_pgm_image(uint8_t *frame,
		 const struct fp_image_frame_params &image_frame_params);

ZTEST(fpsensor_debug, test_upload_pgm_image_wrong_bpp)
{
	std::array<uint8_t, 100> frame{};

	zassert_equal(upload_pgm_image(frame.data(), { .bpp = 0 }),
		      EC_ERROR_UNKNOWN);

	zassert_equal(upload_pgm_image(frame.data(), { .bpp = 17 }),
		      EC_ERROR_UNKNOWN);

	zassert_equal(upload_pgm_image(frame.data(), { .bpp = 23 }),
		      EC_ERROR_UNKNOWN);
}

ZTEST(fpsensor_debug, test_get_image_frame_params)
{
	struct fingerprint_sensor_info sensor_info{};
	struct fingerprint_image_frame_params
		image_frame_params_arr[NUM_IMAGE_CAPTURE_TYPES] = {};
	uint8_t num_params = NUM_IMAGE_CAPTURE_TYPES;

	zassert_ok(fingerprint_get_info(fp_sensor_dev, &sensor_info,
					image_frame_params_arr, &num_params));
	zassert_true(
		num_params == NUM_IMAGE_CAPTURE_TYPES,
		"fingerprint_get_info returned different params than expected");

	constexpr auto kCaptureTypesArray = std::to_array(
		{ FP_CAPTURE_VENDOR_FORMAT, FP_CAPTURE_DEFECT_PXL_TEST,
		  FP_CAPTURE_ABNORMAL_TEST, FP_CAPTURE_NOISE_TEST,
		  FP_CAPTURE_SIMPLE_IMAGE, FP_CAPTURE_PATTERN0,
		  FP_CAPTURE_PATTERN1, FP_CAPTURE_QUALITY_TEST,
		  FP_CAPTURE_RESET_TEST, FP_CAPTURE_TYPE_MAX });
	constexpr struct fp_image_frame_params zero_params{};

	for (enum fp_capture_type current_capture_type : kCaptureTypesArray) {
		const struct fingerprint_image_frame_params *expected_params =
			nullptr;
		for (size_t j = 0; j < num_params; ++j) {
			if (image_frame_params_arr[j].fp_capture_type ==
			    current_capture_type) {
				expected_params = &image_frame_params_arr[j];
				break;
			}
		}

		struct fp_image_frame_params image_frame_params{};
		int rv = get_image_frame_params(image_frame_params,
						current_capture_type);

		if (expected_params) {
			zassert_equal(
				rv, EC_RES_SUCCESS,
				"get_image_frame_params failed with error %d for capture type %d",
				rv, current_capture_type);
			zassert_mem_equal(
				&image_frame_params, expected_params,
				sizeof(struct fp_image_frame_params),
				"Struct comparison failed for type %d",
				current_capture_type);
		} else {
			zassert_equal(
				rv, EC_ERROR_INVAL,
				"Expected EC_ERROR_INVAL (%d), but got %d for invalid type",
				EC_ERROR_INVAL, rv);
			zassert_mem_equal(
				&image_frame_params, &zero_params,
				sizeof(struct fp_image_frame_params),
				"Struct contents should not change on failure");
		}
	}
}
```
